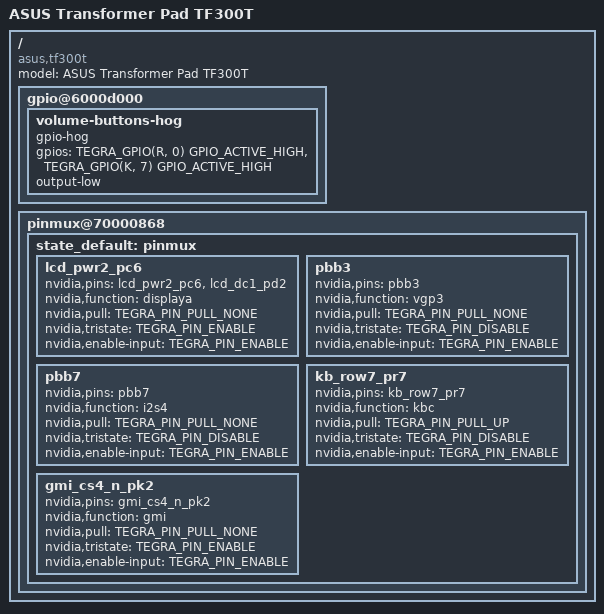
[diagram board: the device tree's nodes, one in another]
// SPDX-License-Identifier: GPL-2.0
/dts-v1/;

#include "tegra30-asus-transformer.dtsi"

/ {
	model = "ASUS Transformer Pad TF300T";
	compatible = "asus,tf300t", "nvidia,tegra30";

	gpio@6000d000 {
		volume-buttons-hog {
			gpio-hog;
			gpios = <TEGRA_GPIO(R, 0) GPIO_ACTIVE_HIGH>,
				<TEGRA_GPIO(K, 7) GPIO_ACTIVE_HIGH>;
			output-low;
		};
	};

	pinmux@70000868 {
		state_default: pinmux {
			lcd_pwr2_pc6 {
				nvidia,pins = "lcd_pwr2_pc6",
						"lcd_dc1_pd2";
				nvidia,function = "displaya";
				nvidia,pull = <TEGRA_PIN_PULL_NONE>;
				nvidia,tristate = <TEGRA_PIN_ENABLE>;
				nvidia,enable-input = <TEGRA_PIN_ENABLE>;
			};

			pbb3 {
				nvidia,pins = "pbb3";
				nvidia,function = "vgp3";
				nvidia,pull = <TEGRA_PIN_PULL_NONE>;
				nvidia,tristate = <TEGRA_PIN_DISABLE>;
				nvidia,enable-input = <TEGRA_PIN_ENABLE>;
			};

			pbb7 {
				nvidia,pins = "pbb7";
				nvidia,function = "i2s4";
				nvidia,pull = <TEGRA_PIN_PULL_NONE>;
				nvidia,tristate = <TEGRA_PIN_DISABLE>;
				nvidia,enable-input = <TEGRA_PIN_ENABLE>;
			};

			kb_row7_pr7 {
				nvidia,pins = "kb_row7_pr7";
				nvidia,function = "kbc";
				nvidia,pull = <TEGRA_PIN_PULL_UP>;
				nvidia,tristate = <TEGRA_PIN_DISABLE>;
				nvidia,enable-input = <TEGRA_PIN_ENABLE>;
			};

			gmi_cs4_n_pk2 {
				nvidia,pins = "gmi_cs4_n_pk2";
				nvidia,function = "gmi";
				nvidia,pull = <TEGRA_PIN_PULL_NONE>;
				nvidia,tristate = <TEGRA_PIN_ENABLE>;
				nvidia,enable-input = <TEGRA_PIN_ENABLE>;
			};
		};
	};
};
